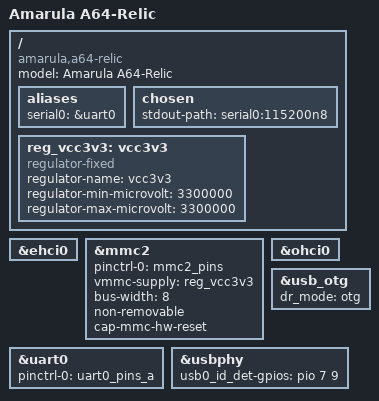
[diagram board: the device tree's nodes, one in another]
// SPDX-License-Identifier: (GPL-2.0+ OR MIT)
/*
 * Copyright (C) 2018 Amarula Solutions B.V.
 * Author: Jagan Teki <jagan@amarulasolutions.com>
 */

/dts-v1/;

#include "sun50i-a64.dtsi"

#include <dt-bindings/gpio/gpio.h>

/ {
	model = "Amarula A64-Relic";
	compatible = "amarula,a64-relic", "allwinner,sun50i-a64";

	aliases {
		serial0 = &uart0;
	};

	chosen {
		stdout-path = "serial0:115200n8";
	};

	reg_vcc3v3: vcc3v3 {
		compatible = "regulator-fixed";
		regulator-name = "vcc3v3";
		regulator-min-microvolt = <3300000>;
		regulator-max-microvolt = <3300000>;
	};
};

&ehci0 {
	status = "okay";
};

&mmc2 {
	pinctrl-names = "default";
	pinctrl-0 = <&mmc2_pins>;
	vmmc-supply = <&reg_vcc3v3>;
	bus-width = <8>;
	non-removable;
	cap-mmc-hw-reset;
	status = "okay";
};

&ohci0 {
	status = "okay";
};

&uart0 {
	pinctrl-names = "default";
	pinctrl-0 = <&uart0_pins_a>;
	status = "okay";
};

&usb_otg {
	dr_mode = "otg";
	status = "okay";
};

&usbphy {
	usb0_id_det-gpios = <&pio 7 9 GPIO_ACTIVE_HIGH>; /* PH9 */
	status = "okay";
};
